AUTOSAR XML (schema 4-0-3)
standard types defined: Boolean, UInt16, UInt32, UInt8
package /AUTOSAR_Platform/DataConstrs
  range DC_Boolean: raw 0..1
  range DC_UInt16: raw 0..65535
  range DC_UInt8: raw 0..255
package /PATAC/MSM/ComponentTypes
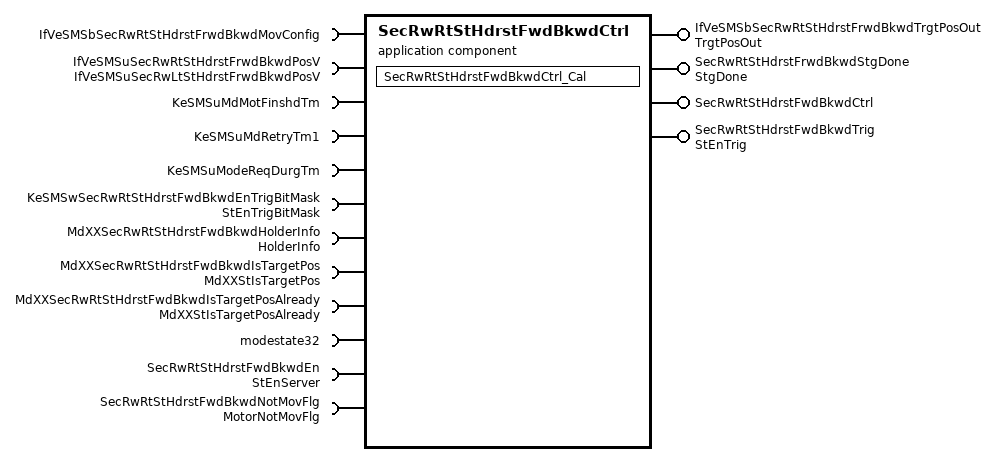
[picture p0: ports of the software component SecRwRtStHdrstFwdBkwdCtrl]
  application sw component type SecRwRtStHdrstFwdBkwdCtrl
    4 x provide port:
      IfVeSMSbSecRwRtStHdrstFrwdBkwdTrgtPosOut: nonqueued-sender-com-spec{data-element=TrgtPosOut/Val, init-value=0}, provided-interface=TrgtPosOut
      SecRwRtStHdrstFrwdBkwdStgDone: nonqueued-sender-com-spec{data-element=StgDone/Val, init-value=0}, provided-interface=StgDone
      SecRwRtStHdrstFwdBkwdCtrl: server-com-spec{operation=Cal, queue-length=1}, provided-interface=SecRwRtStHdrstFwdBkwdCtrl
      SecRwRtStHdrstFwdBkwdTrig: nonqueued-sender-com-spec{data-element=StEnTrig/Val, init-value=0}, provided-interface=StEnTrig
    12 x require port:
      IfVeSMSbSecRwRtStHdrstFrwdBkwdMovConfig: nonqueued-receiver-com-spec{data-element=IfVeSMSbSecRwRtStHdrstFrwdBkwdMovConfig/Val, filter=data-filter-type=ALWAYS, init-value=0}, required-interface=IfVeSMSbSecRwRtStHdrstFrwdBkwdMovConfig
      IfVeSMSuSecRwRtStHdrstFrwdBkwdPosV: nonqueued-receiver-com-spec{data-element=IfVeSMSuSecRwLtStHdrstFrwdBkwdPosV/Val, filter=data-filter-type=ALWAYS, init-value=0}, required-interface=IfVeSMSuSecRwLtStHdrstFrwdBkwdPosV
      KeSMSuMdMotFinshdTm: parameter-require-com-spec{init-value=0, parameter=KeSMSuMdMotFinshdTm/Val}, required-interface=KeSMSuMdMotFinshdTm
      KeSMSuMdRetryTm1: parameter-require-com-spec{init-value=0, parameter=KeSMSuMdRetryTm1/Val}, required-interface=KeSMSuMdRetryTm1
      KeSMSuModeReqDurgTm: parameter-require-com-spec{init-value=0, parameter=KeSMSuModeReqDurgTm/Val}, required-interface=KeSMSuModeReqDurgTm
      KeSMSwSecRwRtStHdrstFwdBkwdEnTrigBitMask: parameter-require-com-spec{init-value=6153, parameter=StEnTrigBitMask/Val}, required-interface=StEnTrigBitMask
      MdXXSecRwRtStHdrstFwdBkwdHolderInfo: nonqueued-receiver-com-spec{data-element=HolderInfo/Val, filter=data-filter-type=ALWAYS, init-value=0}, required-interface=HolderInfo
      MdXXSecRwRtStHdrstFwdBkwdIsTargetPos: nonqueued-receiver-com-spec{data-element=MdXXStIsTargetPos/Val, filter=data-filter-type=ALWAYS, init-value=0}, required-interface=MdXXStIsTargetPos
      MdXXSecRwRtStHdrstFwdBkwdIsTargetPosAlready: nonqueued-receiver-com-spec{data-element=MdXXStIsTargetPosAlready/Val, filter=data-filter-type=ALWAYS, init-value=0}, required-interface=MdXXStIsTargetPosAlready
      modestate32: nonqueued-receiver-com-spec{data-element=modestate32/Val, filter=data-filter-type=ALWAYS, init-value=0}, required-interface=modestate32
      SecRwRtStHdrstFwdBkwdEn: required-com-specs=[Clear, Get, Set], required-interface=StEnServer
      SecRwRtStHdrstFwdBkwdNotMovFlg: nonqueued-receiver-com-spec{data-element=MotorNotMovFlg/Val, filter=data-filter-type=ALWAYS, init-value=0}, required-interface=MotorNotMovFlg
    behavior SecRwRtStHdrstFwdBkwdCtrl_InternalBehavior
      operation invoked event OIT_SecRwRtStHdrstFwdBkwdCtrl_Cal_SecRwRtStHdrstFwdBkwdCtrl_Cal: start-on-event=SecRwRtStHdrstFwdBkwdCtrl_Cal, operation=SecRwRtStHdrstFwdBkwdCtrl.Cal
      runnable SecRwRtStHdrstFwdBkwdCtrl_Cal
        data-receive-point-by-arguments:
          7 x access:
            REC_IfVeSMSbSecRwRtStHdrstFrwdBkwdMovConfig_Val: accessed-variable=IfVeSMSbSecRwRtStHdrstFrwdBkwdMovConfig.Val
            REC_IfVeSMSuSecRwRtStHdrstFrwdBkwdPosV_Val: accessed-variable=IfVeSMSuSecRwRtStHdrstFrwdBkwdPosV.Val
            REC_MdXXSecRwRtStHdrstFwdBkwdHolderInfo_Val: accessed-variable=MdXXSecRwRtStHdrstFwdBkwdHolderInfo.Val
            REC_MdXXSecRwRtStHdrstFwdBkwdIsTargetPos_Val: accessed-variable=MdXXSecRwRtStHdrstFwdBkwdIsTargetPos.Val
            REC_MdXXSecRwRtStHdrstFwdBkwdIsTargetPosAlready_Val: accessed-variable=MdXXSecRwRtStHdrstFwdBkwdIsTargetPosAlready.Val
            REC_modestate32_Val: accessed-variable=modestate32.Val
            REC_SecRwRtStHdrstFwdBkwdNotMovFlg_Val: accessed-variable=SecRwRtStHdrstFwdBkwdNotMovFlg.Val
        data-send-points:
          access SEND_IfVeSMSbSecRwRtStHdrstFrwdBkwdTrgtPosOut_Val: accessed-variable=IfVeSMSbSecRwRtStHdrstFrwdBkwdTrgtPosOut.Val
          access SEND_SecRwRtStHdrstFrwdBkwdStgDone_Val: accessed-variable=SecRwRtStHdrstFrwdBkwdStgDone.Val
          access SEND_SecRwRtStHdrstFwdBkwdTrig_Val: accessed-variable=SecRwRtStHdrstFwdBkwdTrig.Val
        4 x parameter access:
          PA_KeSMSuMdMotFinshdTm_Val: accessed-parameter=KeSMSuMdMotFinshdTm.Val
          PA_KeSMSuMdRetryTm1_Val: accessed-parameter=KeSMSuMdRetryTm1.Val
          PA_KeSMSuModeReqDurgTm_Val: accessed-parameter=KeSMSuModeReqDurgTm.Val
          PA_KeSMSwSecRwRtStHdrstFwdBkwdEnTrigBitMask_Val: accessed-parameter=KeSMSwSecRwRtStHdrstFwdBkwdEnTrigBitMask.Val
        sync call SC_SecRwRtStHdrstFwdBkwdEn_Get: operation=SecRwRtStHdrstFwdBkwdEn.Get, timeout=0
  swc implementation SecRwRtStHdrstFwdBkwdCtrl_Implementation: behavior=SecRwRtStHdrstFwdBkwdCtrl_InternalBehavior
    code-descriptors:
      code Default: artifact-descriptors=autosar-engineering-object={short-label=Default, category=SWSRC}
package /PATAC/MSM/ModeAdjust/CalPortInterface
  parameter interface KeSMSuMdMotFinshdTm
    parameter data prototype Val: sw-calibration-access=READ-WRITE, type=UInt16
  parameter interface KeSMSuModeReqDurgTm
    parameter data prototype Val: sw-calibration-access=READ-WRITE, type=UInt16
  parameter interface StEnTrigBitMask
    parameter data prototype Val: sw-calibration-access=READ-WRITE, type=UInt32
package /PATAC/MSM/ModeAdjust/PortInterface
  client server interface SecRwRtStHdrstFwdBkwdCtrl
    operation Cal
  client server interface StEnServer
    operation Clear
      arg data: type=UInt8, direction=IN, server-argument-impl-policy=USE-ARGUMENT-TYPE
    operation Get
      arg data: type=UInt32, direction=OUT, server-argument-impl-policy=USE-ARGUMENT-TYPE
    operation Set
      arg data: type=UInt8, direction=IN, server-argument-impl-policy=USE-ARGUMENT-TYPE
  8 x sender receiver interface:
    HolderInfo: invalidation-policy{data-element=HolderInfo/Val, handle-invalid=DONT-INVALIDATE}
      data Val: type=UInt32
    MdXXStIsTargetPos: invalidation-policy{data-element=MdXXStIsTargetPos/Val, handle-invalid=DONT-INVALIDATE}
      data Val: type=UInt32
    MdXXStIsTargetPosAlready: invalidation-policy{data-element=MdXXStIsTargetPosAlready/Val, handle-invalid=DONT-INVALIDATE}
      data Val: type=UInt32
    modestate32: invalidation-policy{data-element=modestate32/Val, handle-invalid=DONT-INVALIDATE}
      data Val: type=UInt32
    MotorNotMovFlg: invalidation-policy{data-element=MotorNotMovFlg/Val, handle-invalid=DONT-INVALIDATE}
      data Val: type=Boolean
    StEnTrig: invalidation-policy{data-element=StEnTrig/Val, handle-invalid=DONT-INVALIDATE}
      data Val: type=Boolean
    StgDone: invalidation-policy{data-element=StgDone/Val, handle-invalid=DONT-INVALIDATE}
      data Val: type=Boolean
    TrgtPosOut: invalidation-policy{data-element=TrgtPosOut/Val, handle-invalid=DONT-INVALIDATE}
      data Val: type=Boolean
package /PATAC/MSM/PortInterfaces
  parameter interface KeSMSuMdRetryTm1
    parameter data prototype Val: sw-calibration-access=READ-WRITE, type=UInt8
  sender receiver interface IfVeSMSbSecRwRtStHdrstFrwdBkwdMovConfig: invalidation-policy{data-element=IfVeSMSbSecRwRtStHdrstFrwdBkwdMovConfig/Val, handle-invalid=DONT-INVALIDATE}
    data Val: type=Boolean
  sender receiver interface IfVeSMSuSecRwLtStHdrstFrwdBkwdPosV: invalidation-policy{data-element=IfVeSMSuSecRwLtStHdrstFrwdBkwdPosV/Val, handle-invalid=DONT-INVALIDATE}
    data Val: type=Boolean
